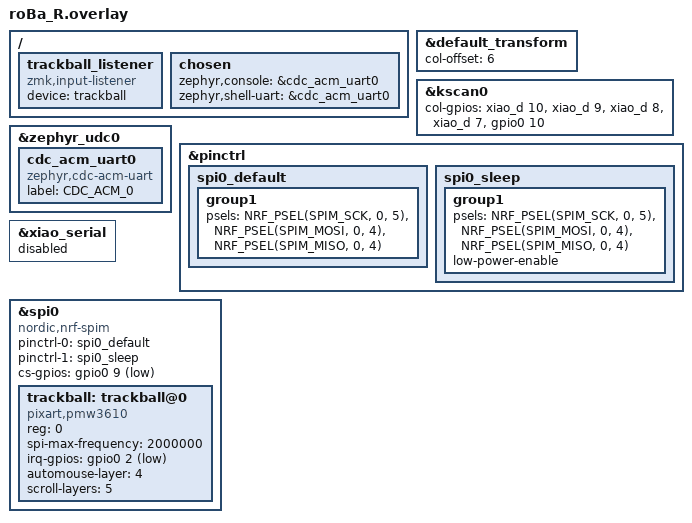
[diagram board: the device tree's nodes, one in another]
#include "roBa.dtsi"

&default_transform {
    col-offset = <6>;
};

&kscan0 {
        col-gpios
            = <&xiao_d 10 GPIO_ACTIVE_HIGH>
            , <&xiao_d 9 GPIO_ACTIVE_HIGH> 
            , <&xiao_d 8 GPIO_ACTIVE_HIGH> 
            , <&xiao_d 7 GPIO_ACTIVE_HIGH> 
            , <&gpio0 10 GPIO_ACTIVE_HIGH>
            ;
};

/ {
    trackball_listener {
        compatible = "zmk,input-listener";
        device = <&trackball>;

    };

    /* --- DEBUG: トラックボール無反応の調査用（原因判明後に削除すること） ---
     * xiao_serial (物理UART) をSPIのために無効化しているため、
     * CONFIG_ZMK_USB_LOGGING 用のコンソールをCDC-ACM UARTとして別途用意する。
     */
    chosen {
        zephyr,console = &cdc_acm_uart0;
        zephyr,shell-uart = &cdc_acm_uart0;
    };
    /* --- DEBUG ここまで --- */
};

/* --- DEBUG --- */
&zephyr_udc0 {
    cdc_acm_uart0: cdc_acm_uart0 {
        compatible = "zephyr,cdc-acm-uart";
        label = "CDC_ACM_0";
    };
};
/* --- DEBUG ここまで --- */

&pinctrl {
    spi0_default: spi0_default {
        group1 {
            psels = <NRF_PSEL(SPIM_SCK, 0, 5)>,
                <NRF_PSEL(SPIM_MOSI, 0, 4)>,
                <NRF_PSEL(SPIM_MISO, 0, 4)>;
        };
    };

    spi0_sleep: spi0_sleep {
        group1 {
            psels = <NRF_PSEL(SPIM_SCK, 0, 5)>,
                <NRF_PSEL(SPIM_MOSI, 0, 4)>,
                <NRF_PSEL(SPIM_MISO, 0, 4)>;
            low-power-enable;
        };
    };
};

&xiao_serial { status = "disabled"; };

&spi0 {
    status = "okay";
    compatible = "nordic,nrf-spim";
    pinctrl-0 = <&spi0_default>;
    pinctrl-1 = <&spi0_sleep>;
    pinctrl-names = "default", "sleep";
    cs-gpios = <&gpio0 9 GPIO_ACTIVE_LOW>;

    trackball: trackball@0 {
        status = "okay";
        compatible = "pixart,pmw3610";
        reg = <0>;
        spi-max-frequency = <2000000>;
        irq-gpios = <&gpio0 2 (GPIO_ACTIVE_LOW | GPIO_PULL_UP)>;
        automouse-layer = <4>;
        scroll-layers = <5>;
    };
};


